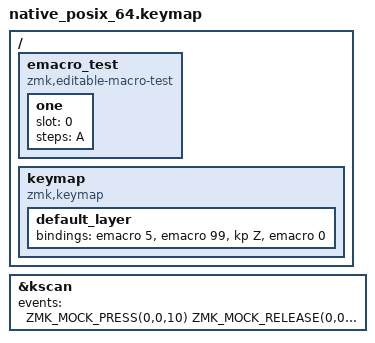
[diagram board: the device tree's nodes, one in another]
/*
 * Copyright (c) 2026 The zmk-editable-macros contributors
 *
 * SPDX-License-Identifier: MIT
 */

/*
 * An empty slot and a slot number that does not exist both do nothing, and the rest of
 * the keyboard carries on working.
 */

#include "../common.dtsi"

/ {
    emacro_test {
        compatible = "zmk,editable-macro-test";

        one {
            slot = <0>;
            steps = <A>;
        };
    };

    keymap {
        compatible = "zmk,keymap";

        default_layer {
            bindings = <&emacro 5 &emacro 99 &kp Z &emacro 0>;
        };
    };
};

&kscan {
    events = <
        ZMK_MOCK_PRESS(0,0,10) ZMK_MOCK_RELEASE(0,0,10)
        ZMK_MOCK_PRESS(0,1,10) ZMK_MOCK_RELEASE(0,1,10)
        ZMK_MOCK_PRESS(1,0,10) ZMK_MOCK_RELEASE(1,0,10)
        ZMK_MOCK_PRESS(1,1,10) ZMK_MOCK_RELEASE(1,1,50)
    >;
};
